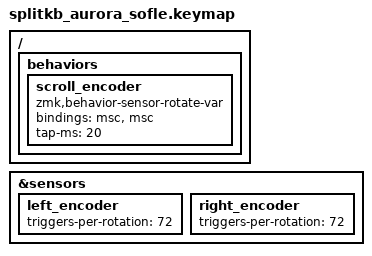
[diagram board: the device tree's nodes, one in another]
#define SELENIUM_KEYMAP_BINDINGS(LOUT1,  LROW1,  RROW1,  ROUT1, \
                                 LOUT2,  LROW2,  RROW2,  ROUT2, \
                                 LOUT3,  LROW3, LENC, RENC, RROW3,  ROUT3, \
                                 LT1, LT2, LT3,  RT3, RT2, RT1) \
    &kp EQUAL &kp N1 &kp N2 &kp N3 &kp N4 &kp N5             &kp N6 &kp N7 &kp N8 &kp N9 &kp N0 &kp MINUS \
    LOUT1     LROW1                                                                      RROW1  ROUT1     \
    LOUT2     LROW2                                                                      RROW2  ROUT2     \
    LOUT3     LROW3                              LENC RENC                               RROW3  ROUT3     \
                     &none  &none  LT1    LT2    LT3   RT3   RT2    RT1    &msc SCRL_UP  &msc SCRL_DOWN

 
&sensors {
    left_encoder {
        triggers-per-rotation = <72>;
    };

    right_encoder {
        triggers-per-rotation = <72>;
    };
};

#define ZMK_POINTING_DEFAULT_MOVE_VAL 1500 
#define ZMK_POINTING_DEFAULT_SCRL_VAL 140

#include <dt-bindings/zmk/pointing.h>

/ {
    behaviors {
        scroll_encoder: scroll_encoder {
            compatible = "zmk,behavior-sensor-rotate-var";
            #sensor-binding-cells = <2>;
            bindings = <&msc>, <&msc>;
            tap-ms = <20>;
        };
    };
};

#include <aekeynox/selenium.keymap>
